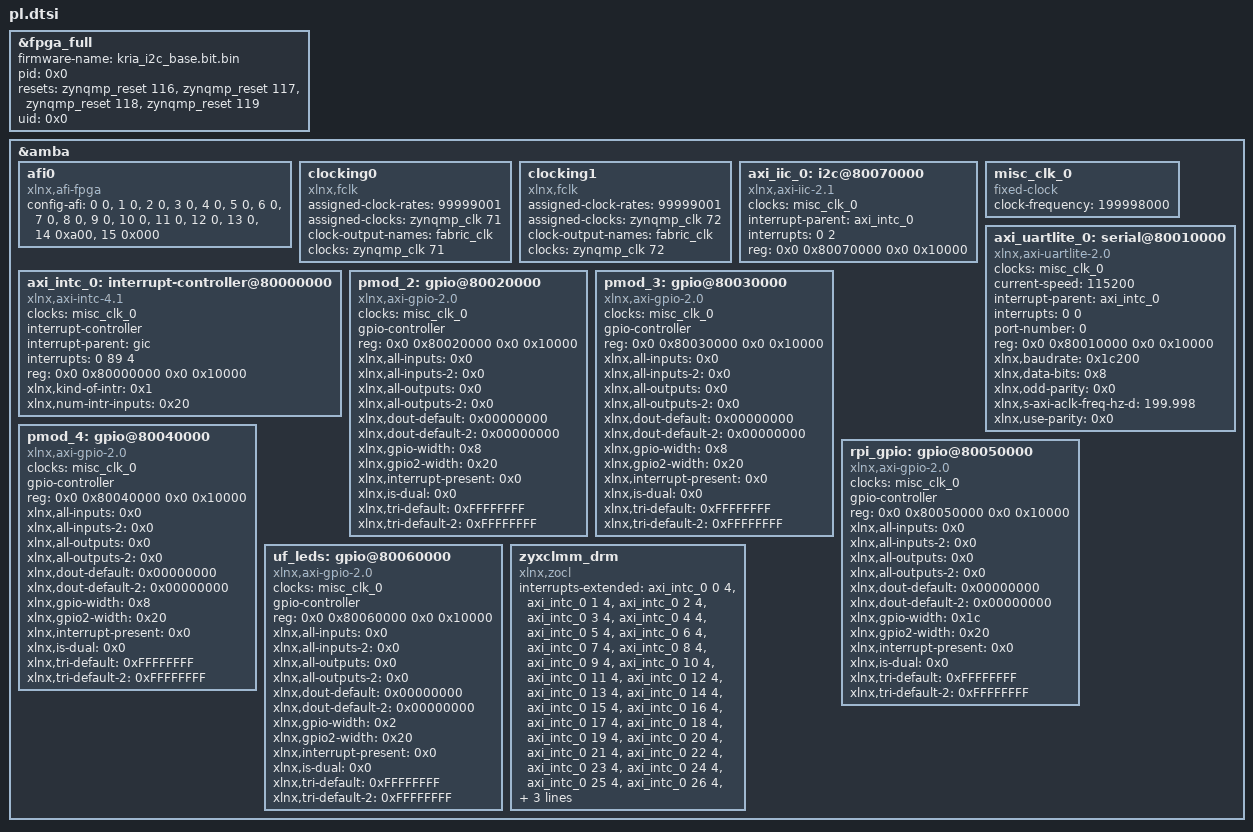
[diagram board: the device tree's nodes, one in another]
/*
 * CAUTION: This file is automatically generated by Xilinx.
 * Version: XSCT 2022.2
 * Today is: Mon Sep  4 22:14:31 2023
 */


/dts-v1/;
/plugin/;
/ {
	fragment@0 {
		target = <&fpga_full>;
		overlay0: __overlay__ {
			#address-cells = <2>;
			#size-cells = <2>;
			firmware-name = "kria_i2c_base.bit.bin";
			pid = <0x0>;
			resets = <&zynqmp_reset 116>, <&zynqmp_reset 117>, <&zynqmp_reset 118>, <&zynqmp_reset 119>;
			uid = <0x0>;
		};
	};
	fragment@1 {
		target = <&amba>;
		overlay1: __overlay__ {
			afi0: afi0 {
				compatible = "xlnx,afi-fpga";
				config-afi = < 0 0>, <1 0>, <2 0>, <3 0>, <4 0>, <5 0>, <6 0>, <7 0>, <8 0>, <9 0>, <10 0>, <11 0>, <12 0>, <13 0>, <14 0xa00>, <15 0x000>;
			};
			clocking0: clocking0 {
				#clock-cells = <0>;
				assigned-clock-rates = <99999001>;
				assigned-clocks = <&zynqmp_clk 71>;
				clock-output-names = "fabric_clk";
				clocks = <&zynqmp_clk 71>;
				compatible = "xlnx,fclk";
			};
			clocking1: clocking1 {
				#clock-cells = <0>;
				assigned-clock-rates = <99999001>;
				assigned-clocks = <&zynqmp_clk 72>;
				clock-output-names = "fabric_clk";
				clocks = <&zynqmp_clk 72>;
				compatible = "xlnx,fclk";
			};
		};
	};
	fragment@2 {
		target = <&amba>;
		overlay2: __overlay__ {
			#address-cells = <2>;
			#size-cells = <2>;
			axi_iic_0: i2c@80070000 {
				#address-cells = <1>;
				#size-cells = <0>;
				clock-names = "s_axi_aclk";
				clocks = <&misc_clk_0>;
				compatible = "xlnx,axi-iic-2.1", "xlnx,xps-iic-2.00.a";
				interrupt-names = "iic2intc_irpt";
				interrupt-parent = <&axi_intc_0>;
				interrupts = <0 2>;
				reg = <0x0 0x80070000 0x0 0x10000>;
			};
			misc_clk_0: misc_clk_0 {
				#clock-cells = <0>;
				clock-frequency = <199998000>;
				compatible = "fixed-clock";
			};
			axi_intc_0: interrupt-controller@80000000 {
				#interrupt-cells = <2>;
				clock-names = "s_axi_aclk";
				clocks = <&misc_clk_0>;
				compatible = "xlnx,axi-intc-4.1", "xlnx,xps-intc-1.00.a";
				interrupt-controller ;
				interrupt-names = "irq";
				interrupt-parent = <&gic>;
				interrupts = <0 89 4>;
				reg = <0x0 0x80000000 0x0 0x10000>;
				xlnx,kind-of-intr = <0x1>;
				xlnx,num-intr-inputs = <0x20>;
			};
			axi_uartlite_0: serial@80010000 {
				clock-names = "s_axi_aclk";
				clocks = <&misc_clk_0>;
				compatible = "xlnx,axi-uartlite-2.0", "xlnx,xps-uartlite-1.00.a";
				current-speed = <115200>;
				device_type = "serial";
				interrupt-names = "interrupt";
				interrupt-parent = <&axi_intc_0>;
				interrupts = <0 0>;
				port-number = <0>;
				reg = <0x0 0x80010000 0x0 0x10000>;
				xlnx,baudrate = <0x1c200>;
				xlnx,data-bits = <0x8>;
				xlnx,odd-parity = <0x0>;
				xlnx,s-axi-aclk-freq-hz-d = "199.998";
				xlnx,use-parity = <0x0>;
			};
			pmod_2: gpio@80020000 {
				#gpio-cells = <2>;
				clock-names = "s_axi_aclk";
				clocks = <&misc_clk_0>;
				compatible = "xlnx,axi-gpio-2.0", "xlnx,xps-gpio-1.00.a";
				gpio-controller ;
				reg = <0x0 0x80020000 0x0 0x10000>;
				xlnx,all-inputs = <0x0>;
				xlnx,all-inputs-2 = <0x0>;
				xlnx,all-outputs = <0x0>;
				xlnx,all-outputs-2 = <0x0>;
				xlnx,dout-default = <0x00000000>;
				xlnx,dout-default-2 = <0x00000000>;
				xlnx,gpio-width = <0x8>;
				xlnx,gpio2-width = <0x20>;
				xlnx,interrupt-present = <0x0>;
				xlnx,is-dual = <0x0>;
				xlnx,tri-default = <0xFFFFFFFF>;
				xlnx,tri-default-2 = <0xFFFFFFFF>;
			};
			pmod_3: gpio@80030000 {
				#gpio-cells = <2>;
				clock-names = "s_axi_aclk";
				clocks = <&misc_clk_0>;
				compatible = "xlnx,axi-gpio-2.0", "xlnx,xps-gpio-1.00.a";
				gpio-controller ;
				reg = <0x0 0x80030000 0x0 0x10000>;
				xlnx,all-inputs = <0x0>;
				xlnx,all-inputs-2 = <0x0>;
				xlnx,all-outputs = <0x0>;
				xlnx,all-outputs-2 = <0x0>;
				xlnx,dout-default = <0x00000000>;
				xlnx,dout-default-2 = <0x00000000>;
				xlnx,gpio-width = <0x8>;
				xlnx,gpio2-width = <0x20>;
				xlnx,interrupt-present = <0x0>;
				xlnx,is-dual = <0x0>;
				xlnx,tri-default = <0xFFFFFFFF>;
				xlnx,tri-default-2 = <0xFFFFFFFF>;
			};
			pmod_4: gpio@80040000 {
				#gpio-cells = <2>;
				clock-names = "s_axi_aclk";
				clocks = <&misc_clk_0>;
				compatible = "xlnx,axi-gpio-2.0", "xlnx,xps-gpio-1.00.a";
				gpio-controller ;
				reg = <0x0 0x80040000 0x0 0x10000>;
				xlnx,all-inputs = <0x0>;
				xlnx,all-inputs-2 = <0x0>;
				xlnx,all-outputs = <0x0>;
				xlnx,all-outputs-2 = <0x0>;
				xlnx,dout-default = <0x00000000>;
				xlnx,dout-default-2 = <0x00000000>;
				xlnx,gpio-width = <0x8>;
				xlnx,gpio2-width = <0x20>;
				xlnx,interrupt-present = <0x0>;
				xlnx,is-dual = <0x0>;
				xlnx,tri-default = <0xFFFFFFFF>;
				xlnx,tri-default-2 = <0xFFFFFFFF>;
			};
			rpi_gpio: gpio@80050000 {
				#gpio-cells = <2>;
				clock-names = "s_axi_aclk";
				clocks = <&misc_clk_0>;
				compatible = "xlnx,axi-gpio-2.0", "xlnx,xps-gpio-1.00.a";
				gpio-controller ;
				reg = <0x0 0x80050000 0x0 0x10000>;
				xlnx,all-inputs = <0x0>;
				xlnx,all-inputs-2 = <0x0>;
				xlnx,all-outputs = <0x0>;
				xlnx,all-outputs-2 = <0x0>;
				xlnx,dout-default = <0x00000000>;
				xlnx,dout-default-2 = <0x00000000>;
				xlnx,gpio-width = <0x1c>;
				xlnx,gpio2-width = <0x20>;
				xlnx,interrupt-present = <0x0>;
				xlnx,is-dual = <0x0>;
				xlnx,tri-default = <0xFFFFFFFF>;
				xlnx,tri-default-2 = <0xFFFFFFFF>;
			};
			uf_leds: gpio@80060000 {
				#gpio-cells = <2>;
				clock-names = "s_axi_aclk";
				clocks = <&misc_clk_0>;
				compatible = "xlnx,axi-gpio-2.0", "xlnx,xps-gpio-1.00.a";
				gpio-controller ;
				reg = <0x0 0x80060000 0x0 0x10000>;
				xlnx,all-inputs = <0x0>;
				xlnx,all-inputs-2 = <0x0>;
				xlnx,all-outputs = <0x0>;
				xlnx,all-outputs-2 = <0x0>;
				xlnx,dout-default = <0x00000000>;
				xlnx,dout-default-2 = <0x00000000>;
				xlnx,gpio-width = <0x2>;
				xlnx,gpio2-width = <0x20>;
				xlnx,interrupt-present = <0x0>;
				xlnx,is-dual = <0x0>;
				xlnx,tri-default = <0xFFFFFFFF>;
				xlnx,tri-default-2 = <0xFFFFFFFF>;
			};
			zyxclmm_drm {
				compatible = "xlnx,zocl";
				interrupts-extended = <&axi_intc_0 0 4>, <&axi_intc_0 1 4>, <&axi_intc_0 2 4>, <&axi_intc_0 3 4>, <&axi_intc_0 4 4>, <&axi_intc_0 5 4>, <&axi_intc_0 6 4>, <&axi_intc_0 7 4>, <&axi_intc_0 8 4>, <&axi_intc_0 9 4>,
<&axi_intc_0 10 4>, <&axi_intc_0 11 4>, <&axi_intc_0 12 4>, <&axi_intc_0 13 4>, <&axi_intc_0 14 4>,
<&axi_intc_0 15 4>, <&axi_intc_0 16 4>, <&axi_intc_0 17 4>, <&axi_intc_0 18 4>, <&axi_intc_0 19 4>,
<&axi_intc_0 20 4>, <&axi_intc_0 21 4>, <&axi_intc_0 22 4>, <&axi_intc_0 23 4>, <&axi_intc_0 24 4>,
<&axi_intc_0 25 4>, <&axi_intc_0 26 4>, <&axi_intc_0 27 4>, <&axi_intc_0 28 4>, <&axi_intc_0 29 4>,
<&axi_intc_0 30 4>, <&axi_intc_0 31 4 >;
			};
		};
	};
};
